# I3C0_S_ECC_AGGR_CFG register map
Vendor: Texas Instruments
Peripheral module from a debugger description file (folder J7VCL).
Registers are 32-bit, access not given, reset 0x0 unless marked. A register's access mark holds for its fields unless they carry their own. Offsets are as the file gives them; lines under a group give offsets from that group; [hi:lo] are bit positions; {n}, {i} and the like mark numbered series; 'fields as' and 'values as' point back to an identical list; <NAME> marks a mode.

## I3C0_S_ECC_AGGR_CFG
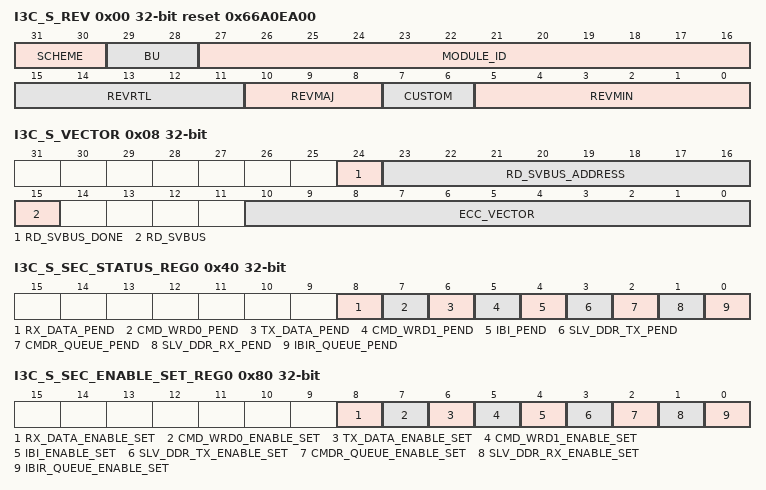
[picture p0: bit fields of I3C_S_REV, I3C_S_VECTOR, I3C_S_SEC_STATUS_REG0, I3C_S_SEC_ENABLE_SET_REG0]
0x00 I3C_S_REV ro reset 0x66A0EA00 — Return to the . Revision parameters
  [31:30] SCHEME
  [29:28] BU
  [27:16] MODULE_ID
  [15:11] REVRTL — RTL version
  [10:8] REVMAJ — Major version
  [7:6] CUSTOM — Custom version
  [5:0] REVMIN — Minor version
0x08 I3C_S_VECTOR — Return to the . ECC Vector Register
  [24] RD_SVBUS_DONE — Status to indicate if read on serial VBUS is complete, write of any value will clear this bit. (access RW1C)
  [23:16] RD_SVBUS_ADDRESS rw — Read address
  [15] RD_SVBUS — Write 1 to trigger a read on the serial VBUS (access RW1S)
  [10:0] ECC_VECTOR rw — Value written to select the corresponding ECC RAM for control or status
0x0C I3C_S_STAT ro reset 0x9 — Return to the . Misc Status
  [10:0] NUM_RAMS — Indicates the number of RAMS serviced by the ECC aggregator
0x10 I3C_S_RESERVED_SVBUS_y rw — Return to the . Reference other documents that contain the ECC RAM wrapper and EDC controller serial vbus register sets. Offset = 10h + (y * 4h); where y = 0h to 7h
  [31:0] DATA — Serial VBUS register data
0x3C I3C_S_SEC_EOI_REG — Return to the . EOI Register
  [0] EOI_WR — EOI Register (access RW1S)
0x40 I3C_S_SEC_STATUS_REG0 — Return to the . Interrupt Status Register 0
  [8] RX_DATA_PEND — Interrupt Pending Status for rx_data_pend (access RW1S)
  [7] CMD_WRD0_PEND — Interrupt Pending Status for cmd_wrd0_pend (access RW1S)
  [6] TX_DATA_PEND — Interrupt Pending Status for tx_data_pend (access RW1S)
  [5] CMD_WRD1_PEND — Interrupt Pending Status for cmd_wrd1_pend (access RW1S)
  [4] IBI_PEND — Interrupt Pending Status for ibi_pend (access RW1S)
  [3] SLV_DDR_TX_PEND — Interrupt Pending Status for slv_ddr_tx_pend (access RW1S)
  [2] CMDR_QUEUE_PEND — Interrupt Pending Status for cmdr_queue_pend (access RW1S)
  [1] SLV_DDR_RX_PEND — Interrupt Pending Status for slv_ddr_rx_pend (access RW1S)
  [0] IBIR_QUEUE_PEND — Interrupt Pending Status for ibir_queue_pend (access RW1S)
0x80 I3C_S_SEC_ENABLE_SET_REG0 — Return to the . Interrupt Enable Set Register 0
  [8] RX_DATA_ENABLE_SET — Interrupt Enable Set Register for rx_data_pend (access RW1S)
  [7] CMD_WRD0_ENABLE_SET — Interrupt Enable Set Register for cmd_wrd0_pend (access RW1S)
  [6] TX_DATA_ENABLE_SET — Interrupt Enable Set Register for tx_data_pend (access RW1S)
  [5] CMD_WRD1_ENABLE_SET — Interrupt Enable Set Register for cmd_wrd1_pend (access RW1S)
  [4] IBI_ENABLE_SET — Interrupt Enable Set Register for ibi_pend (access RW1S)
  [3] SLV_DDR_TX_ENABLE_SET — Interrupt Enable Set Register for slv_ddr_tx_pend (access RW1S)
  [2] CMDR_QUEUE_ENABLE_SET — Interrupt Enable Set Register for cmdr_queue_pend (access RW1S)
  [1] SLV_DDR_RX_ENABLE_SET — Interrupt Enable Set Register for slv_ddr_rx_pend (access RW1S)
  [0] IBIR_QUEUE_ENABLE_SET — Interrupt Enable Set Register for ibir_queue_pend (access RW1S)
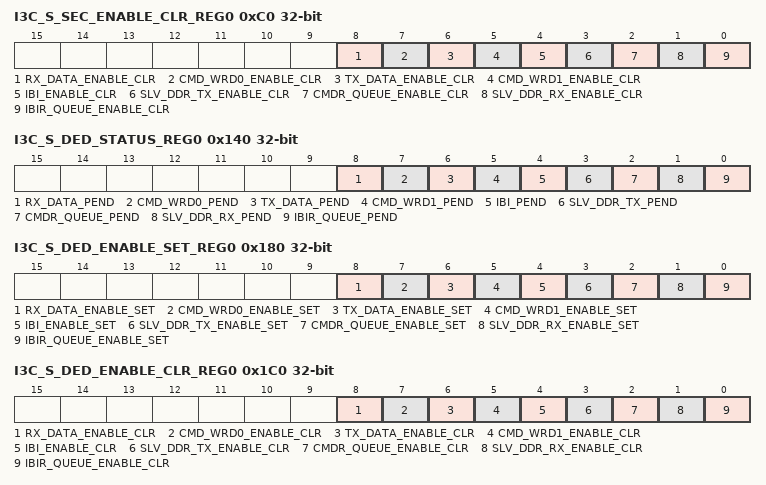
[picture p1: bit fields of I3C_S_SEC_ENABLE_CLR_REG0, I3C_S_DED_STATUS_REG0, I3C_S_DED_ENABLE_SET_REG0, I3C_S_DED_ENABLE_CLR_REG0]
0xC0 I3C_S_SEC_ENABLE_CLR_REG0 — Return to the . Interrupt Enable Clear Register 0
  [8] RX_DATA_ENABLE_CLR — Interrupt Enable Clear Register for rx_data_pend (access RW1C)
  [7] CMD_WRD0_ENABLE_CLR — Interrupt Enable Clear Register for cmd_wrd0_pend (access RW1C)
  [6] TX_DATA_ENABLE_CLR — Interrupt Enable Clear Register for tx_data_pend (access RW1C)
  [5] CMD_WRD1_ENABLE_CLR — Interrupt Enable Clear Register for cmd_wrd1_pend (access RW1C)
  [4] IBI_ENABLE_CLR — Interrupt Enable Clear Register for ibi_pend (access RW1C)
  [3] SLV_DDR_TX_ENABLE_CLR — Interrupt Enable Clear Register for slv_ddr_tx_pend (access RW1C)
  [2] CMDR_QUEUE_ENABLE_CLR — Interrupt Enable Clear Register for cmdr_queue_pend (access RW1C)
  [1] SLV_DDR_RX_ENABLE_CLR — Interrupt Enable Clear Register for slv_ddr_rx_pend (access RW1C)
  [0] IBIR_QUEUE_ENABLE_CLR — Interrupt Enable Clear Register for ibir_queue_pend (access RW1C)
0x13C I3C_S_DED_EOI_REG — Return to the . EOI Register
  [0] EOI_WR — EOI Register (access RW1S)
0x140 I3C_S_DED_STATUS_REG0 — Return to the . Interrupt Status Register 0
  fields as I3C_S_SEC_STATUS_REG0
0x180 I3C_S_DED_ENABLE_SET_REG0 — Return to the . Interrupt Enable Set Register 0
  fields as I3C_S_SEC_ENABLE_SET_REG0
0x1C0 I3C_S_DED_ENABLE_CLR_REG0 — Return to the . Interrupt Enable Clear Register 0
  fields as I3C_S_SEC_ENABLE_CLR_REG0
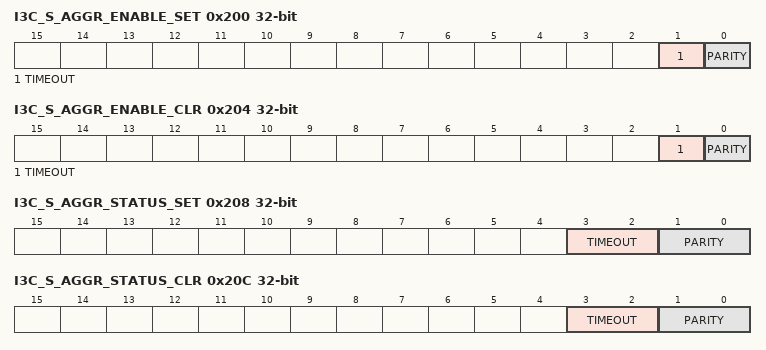
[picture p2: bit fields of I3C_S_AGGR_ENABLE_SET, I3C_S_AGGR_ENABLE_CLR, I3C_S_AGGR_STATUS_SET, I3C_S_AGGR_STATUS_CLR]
0x200 I3C_S_AGGR_ENABLE_SET — Return to the . AGGR interrupt enable set Register
  [1] TIMEOUT — interrupt enable set for svbus timeout errors (access RW1S)
  [0] PARITY — interrupt enable set for parity errors (access RW1S)
0x204 I3C_S_AGGR_ENABLE_CLR — Return to the . AGGR interrupt enable clear Register
  [1] TIMEOUT — interrupt enable clear for svbus timeout errors (access RW1C)
  [0] PARITY — interrupt enable clear for parity errors (access RW1C)
0x208 I3C_S_AGGR_STATUS_SET — Return to the . AGGR interrupt status set Register
  [3:2] TIMEOUT — interrupt status set for svbus timeout errors (access RWincr)
  [1:0] PARITY — interrupt status set for parity errors (access RWincr)
0x20C I3C_S_AGGR_STATUS_CLR — Return to the . AGGR interrupt status clear Register
  [3:2] TIMEOUT — interrupt status clear for svbus timeout errors (access RWdecr)
  [1:0] PARITY — interrupt status clear for parity errors (access RWdecr)
